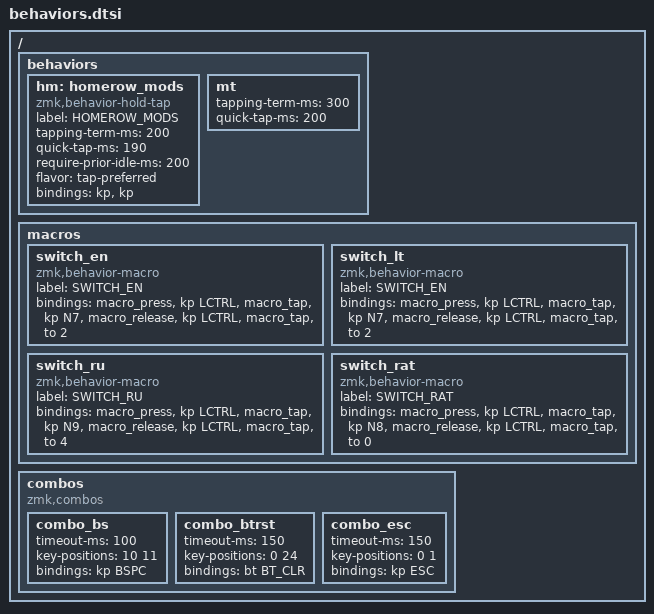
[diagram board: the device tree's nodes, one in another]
/ {
    behaviors {
        hm: homerow_mods {
            compatible = "zmk,behavior-hold-tap";
            label = "HOMEROW_MODS";
            #binding-cells = <2>;
            tapping-term-ms = <200>;
            quick-tap-ms = <190>;
            require-prior-idle-ms = <200>;
            flavor = "tap-preferred";  // исправлена опечатка
            bindings = <&kp>, <&kp>;
        };
        
        mt {
            tapping-term-ms = <300>;
            quick-tap-ms = <200>;
        };
    };

    macros {
        // EN: Ctrl+7 + переключение на слой 0
        switch_en: switch_en {
            compatible = "zmk,behavior-macro";
            label = "SWITCH_EN";
            #binding-cells = <0>;
            bindings = <&macro_press &kp LCTRL>
                     , <&macro_tap &kp N7>
                     , <&macro_release &kp LCTRL>
                     , <&macro_tap &to 2>;
        };

        // LT: Ctrl+8 + переключение на     слой
        switch_lt: switch_lt {
            compatible = "zmk,behavior-macro";
            label = "SWITCH_EN";
            #binding-cells = <0>;
            bindings = <&macro_press &kp LCTRL>
                     , <&macro_tap &kp N7>
                     , <&macro_release &kp LCTRL>
                     , <&macro_tap &to 2>;
        };

        // RU: Ctrl+9 + переключение на русский слой
        switch_ru: switch_ru {
            compatible = "zmk,behavior-macro";
            label = "SWITCH_RU";
            #binding-cells = <0>;
            bindings = <&macro_press &kp LCTRL>
                     , <&macro_tap &kp N9>
                     , <&macro_release &kp LCTRL>
                     , <&macro_tap &to 4>;
        };

        // RAT: Ctrl+8 + переключение на ратисе
        switch_rat: switch_rat {
            compatible = "zmk,behavior-macro";
            label = "SWITCH_RAT";
            #binding-cells = <0>;
            bindings = <&macro_press &kp LCTRL>
                     , <&macro_tap &kp N8>
                     , <&macro_release &kp LCTRL>
                     , <&macro_tap &to 0>;
        };
    };

    combos {
        compatible = "zmk,combos";
        combo_bs {
            timeout-ms = <100>;
            key-positions = <10 11>;
            bindings = <&kp BSPC>;
        };

        combo_btrst {
            timeout-ms = <150>;
            key-positions = <0 24>;
            bindings = <&bt BT_CLR>;
        };

        combo_esc {
            timeout-ms = <150>;
            key-positions = <0 1>;
            bindings = <&kp ESC>;
        };
    };
};
